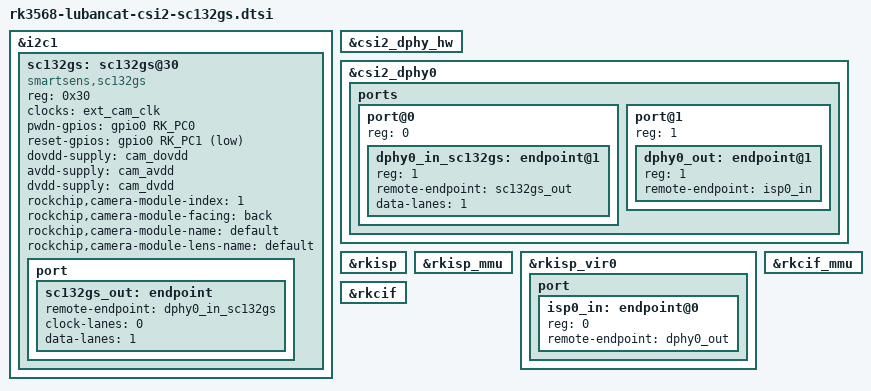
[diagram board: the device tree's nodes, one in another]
// SPDX-License-Identifier: (GPL-2.0+ OR MIT)
/*
 * Copyright (c) 2020 Rockchip Electronics Co., Ltd.
 *
 */

&i2c1 {
	sc132gs: sc132gs@30 {
		compatible = "smartsens,sc132gs";
		status = "okay";
		reg = <0x30>;
		clocks = <&ext_cam_clk>;
		clock-names = "xvclk";

		pwdn-gpios = <&gpio0 RK_PC0 GPIO_ACTIVE_HIGH>;
		reset-gpios = <&gpio0 RK_PC1 GPIO_ACTIVE_LOW>;
		dovdd-supply= <&cam_dovdd>; /* 1.8v */
		avdd-supply = <&cam_avdd>;  /* 2.8v */
		dvdd-supply = <&cam_dvdd>;  /* 1.2v */

		rockchip,camera-module-index = <1>;
		rockchip,camera-module-facing = "back";
		rockchip,camera-module-name = "default";
		rockchip,camera-module-lens-name = "default";

		port {
			sc132gs_out: endpoint {
				remote-endpoint = <&dphy0_in_sc132gs>;
				clock-lanes = <0>;
				data-lanes = <1>;
			};
		};
	};
};

&csi2_dphy_hw {
	status = "okay";
};

&csi2_dphy0 {
	status = "okay";
	
	ports {
		#address-cells = <1>;
		#size-cells = <0>;

		port@0 {
			reg = <0>;
			#address-cells = <1>;
			#size-cells = <0>;

			dphy0_in_sc132gs: endpoint@1 {
				reg = <1>;
				remote-endpoint = <&sc132gs_out>;
				data-lanes = <1>;
			};
		};

		port@1 {
			reg = <1>;
			#address-cells = <1>;
			#size-cells = <0>;

			dphy0_out: endpoint@1 {
				reg = <1>;
				remote-endpoint = <&isp0_in>;
			};
		};
	};
};

&rkisp {
	status = "okay";
};

&rkisp_mmu {
	status = "okay";
};

&rkisp_vir0 {
	status = "okay";

	port {
		#address-cells = <1>;
		#size-cells = <0>;

		isp0_in: endpoint@0 {
			reg = <0>;
			// csi2 dphy端的 port名
			remote-endpoint = <&dphy0_out>;
		};
	};
};

&rkcif_mmu {
	status = "okay";
};

&rkcif {
	status = "okay";
};

